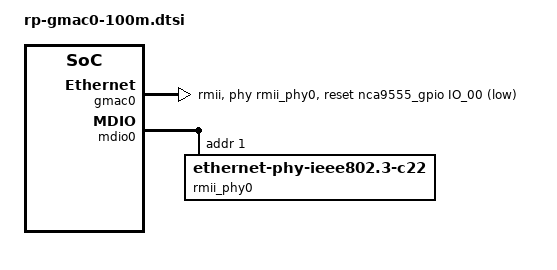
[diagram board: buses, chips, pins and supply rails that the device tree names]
&gmac0 {
    status = "okay";
    /* Use rgmii-rxid mode to disable rx delay inside Soc */
    phy-mode = "rmii";
    clock_in_out = "output";
    snps,reset-gpio = <&nca9555_gpio IO_00 GPIO_ACTIVE_LOW>;
    snps,reset-active-low;
    /* Reset time is 20ms, 100ms for rtl8211f */
    snps,reset-delays-us = <0 10000 100000>;
    compatible = "rockchip,rk3506-gmac", "snps,dwmac-4.20a";
    tx_delay = <0x1a>;
    rx_delay = <0x21>;
    phy-handle = <&rmii_phy0>;
    pinctrl-names = "default";    
    pinctrl-0 = <&eth_rmii0_miim_pins
                &eth_rmii0_tx_bus2_pins
                &eth_rmii0_rx_bus2_pins
                &eth_rmii0_clk_pins>;		
};

&mdio0 {
    rmii_phy0: phy@1 {
        compatible = "ethernet-phy-ieee802.3-c22";
        reg = <0x1>;
        //clocks = <&cru REFCLKO25M_GMAC0_OUT>;
    };
};



